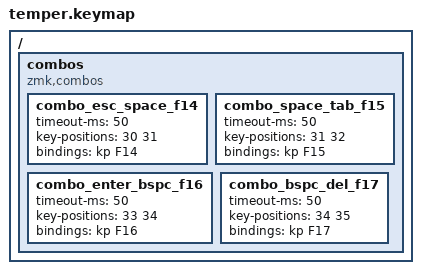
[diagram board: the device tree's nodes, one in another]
// Copyright 2024 Manna Harbour
// https://github.com/manna-harbour/miryoku

#include "../miryoku/custom_config.h"
#include "../miryoku/mapping/36/minidox.h"
#include "../miryoku/miryoku.dtsi"

/ {
  combos {
    compatible = "zmk,combos";
    combo_esc_space_f14 {
      timeout-ms = <50>;
      key-positions = <30 31>;
      bindings = <&kp F14>;
    };
    combo_space_tab_f15 {
      timeout-ms = <50>;
      key-positions = <31 32>;
      bindings = <&kp F15>;
    };
    combo_enter_bspc_f16 {
      timeout-ms = <50>;
      key-positions = <33 34>;
      bindings = <&kp F16>;
    };
    combo_bspc_del_f17 {
      timeout-ms = <50>;
      key-positions = <34 35>;
      bindings = <&kp F17>;
    };
  };
};
